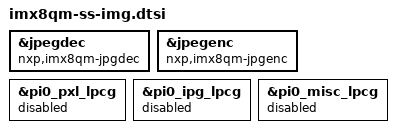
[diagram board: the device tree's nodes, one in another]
// SPDX-License-Identifier: GPL-2.0+
/*
 * Copyright 2021 NXP
 */

&jpegdec {
	compatible = "nxp,imx8qm-jpgdec", "nxp,imx8qxp-jpgdec";
};

&jpegenc {
	compatible = "nxp,imx8qm-jpgenc", "nxp,imx8qxp-jpgenc";
};

&pi0_pxl_lpcg {
	status = "disabled";
};

&pi0_ipg_lpcg {
	status = "disabled";
};

&pi0_misc_lpcg {
	status = "disabled";
};
